# STM32F427 register map
File version: 1.4
CPU: CM4 r0p1, little endian, MPU, FPU, 4 interrupt priority bits
Registers are 32-bit, read-write, reset 0x0 unless marked. A register's access mark holds for its fields unless they carry their own. Offsets are from the block's base; [hi:lo] are bit positions; {n}, {i} and the like mark numbered series.

## OTG_FS_PWRCLK — USB on the go full speed
Base 0x50000E00
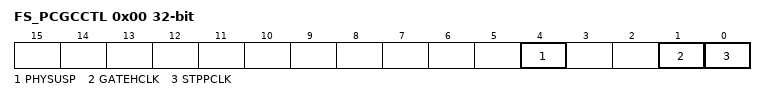
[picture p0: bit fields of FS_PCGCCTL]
0x00 FS_PCGCCTL — OTG_FS power and clock gating control register (OTG_FS_PCGCCTL)
  [4] PHYSUSP — PHY Suspended
  [1] GATEHCLK
  [0] STPPCLK — Stop PHY clock

## NVIC — Nested Vectored Interrupt Controller
Base 0xE000E100
{0x0+4i} ISER{i} (i=0..2) — Interrupt Set-Enable Register
  [31:0] SETENA
{0x80+4i} ICER{i} (i=0..2) — Interrupt Clear-Enable Register
  [31:0] CLRENA
{0x100+4i} ISPR{i} (i=0..2) — Interrupt Set-Pending Register
  [31:0] SETPEND
{0x180+4i} ICPR{i} (i=0..2) — Interrupt Clear-Pending Register
  [31:0] CLRPEND
{0x200+4i} IABR{i} ro (i=0..2) — Interrupt Active Bit Register
  [31:0] ACTIVE
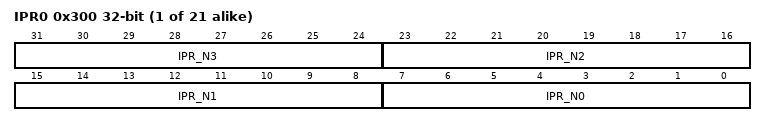
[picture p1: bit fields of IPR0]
{0x300+4i} IPR{i} (i=0..20) — Interrupt Priority Register
  [8n+7:8n] IPR_N{n} (n=0..3)

## FLASH
Base 0x40023C00
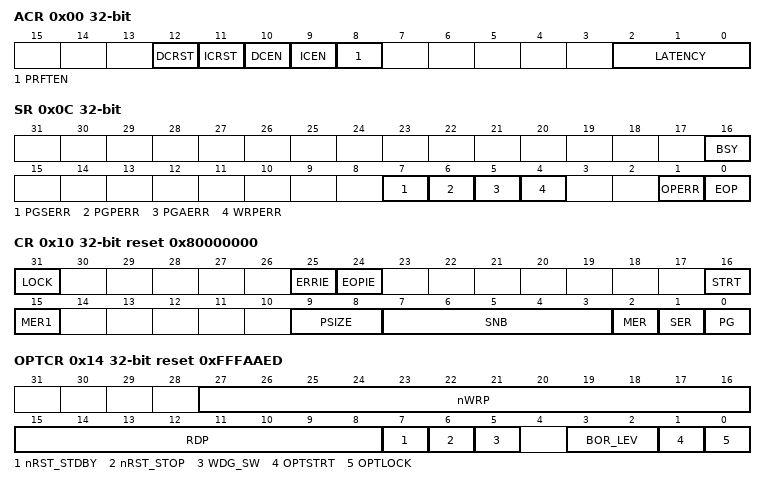
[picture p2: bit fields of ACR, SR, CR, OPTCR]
0x00 ACR access per field — Flash access control register
  [12] DCRST rw — Data cache reset
  [11] ICRST wo — Instruction cache reset
  [10] DCEN rw — Data cache enable
  [9] ICEN rw — Instruction cache enable
  [8] PRFTEN rw — Prefetch enable
  [2:0] LATENCY rw
0x04 KEYR wo — Flash key register
  [31:0] KEY — FPEC key
0x08 OPTKEYR wo — Flash option key register
  [31:0] OPTKEY — Option byte key
0x0C SR access per field — Status register
  [16] BSY ro — Busy
  [7] PGSERR rw — Programming sequence error
  [6] PGPERR rw — Programming parallelism error
  [5] PGAERR rw — Programming alignment error
  [4] WRPERR rw — Write protection error
  [1] OPERR rw — Operation error
  [0] EOP rw — End of operation
0x10 CR reset 0x80000000 — Control register
  [31] LOCK
  [25] ERRIE — Error interrupt enable
  [24] EOPIE — End of operation interrupt enable
  [16] STRT — Start
  [15] MER1 — Mass Erase of sectors 12 to 23
  [9:8] PSIZE — Program size
  [7:3] SNB — Sector number
  [2] MER — Mass Erase of sectors 0 to 11
  [1] SER — Sector Erase
  [0] PG — Programming
0x14 OPTCR reset 0xFFFAAED — Flash option control register
  [27:16] nWRP — Not write protect
  [15:8] RDP — Read protect
  [7] nRST_STDBY — nRST_STDBY User option bytes
  [6] nRST_STOP — nRST_STOP User option bytes
  [5] WDG_SW — WDG_SW User option bytes
  [3:2] BOR_LEV — BOR reset Level
  [1] OPTSTRT — Option start
  [0] OPTLOCK — Option lock
0x18 OPTCR1 reset 0xFFF0000 — Flash option control register 1
  [27:16] nWRP — Not write protect

## EXTI — External interrupt/event controller
Base 0x40013C00
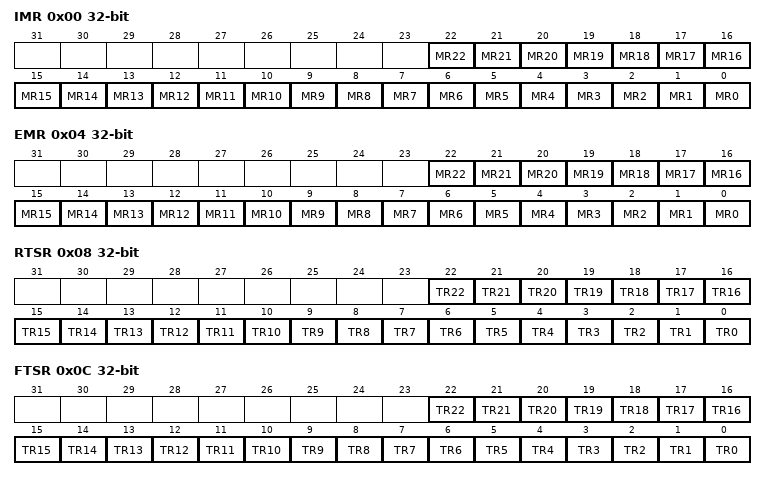
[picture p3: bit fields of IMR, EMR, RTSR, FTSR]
0x00 IMR — Interrupt mask register (EXTI_IMR)
  [n] MR{n} (n=0..22) — Interrupt Mask on line {n}
0x04 EMR — Event mask register (EXTI_EMR)
  [n] MR{n} (n=0..22) — Event Mask on line {n}
0x08 RTSR — Rising Trigger selection register (EXTI_RTSR)
  [n] TR{n} (n=0..22) — Rising trigger event configuration of line {n}
0x0C FTSR — Falling Trigger selection register (EXTI_FTSR)
  [n] TR{n} (n=0..22) — Falling trigger event configuration of line {n}
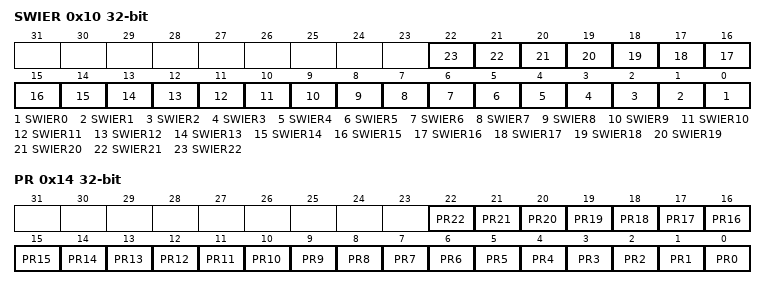
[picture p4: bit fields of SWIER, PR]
0x10 SWIER — Software interrupt event register (EXTI_SWIER)
  [n] SWIER{n} (n=0..22) — Software Interrupt on line {n}
0x14 PR — Pending register (EXTI_PR)
  [n] PR{n} (n=0..22) — Pending bit {n}

## OTG_HS_PWRCLK — USB on the go high speed
Base 0x40040E00
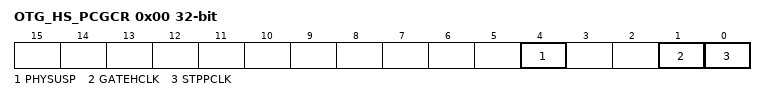
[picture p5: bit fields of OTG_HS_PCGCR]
0x00 OTG_HS_PCGCR — Power and clock gating control register
  [4] PHYSUSP — PHY suspended
  [1] GATEHCLK
  [0] STPPCLK — Stop PHY clock

## I2C3 — Inter-integrated circuit
Base 0x40005C00
Same registers: I2C1 0x40005400, I2C2 0x40005800
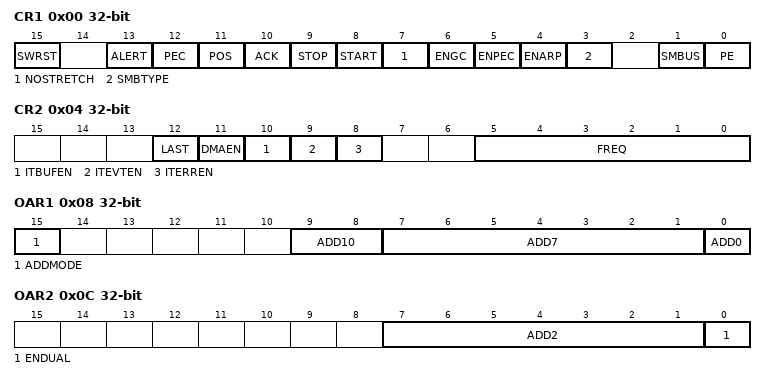
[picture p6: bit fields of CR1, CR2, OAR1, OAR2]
0x00 CR1 — Control register 1
  [15] SWRST — Software reset
  [13] ALERT — SMBus alert
  [12] PEC — Packet error checking
  [11] POS — Acknowledge/PEC Position (for data reception)
  [10] ACK — Acknowledge enable
  [9] STOP — Stop generation
  [8] START — Start generation
  [7] NOSTRETCH — Clock stretching disable (Slave mode)
  [6] ENGC — General call enable
  [5] ENPEC — PEC enable
  [4] ENARP — ARP enable
  [3] SMBTYPE — SMBus type
  [1] SMBUS — SMBus mode
  [0] PE — Peripheral enable
0x04 CR2 — Control register 2
  [12] LAST — DMA last transfer
  [11] DMAEN — DMA requests enable
  [10] ITBUFEN — Buffer interrupt enable
  [9] ITEVTEN — Event interrupt enable
  [8] ITERREN — Error interrupt enable
  [5:0] FREQ — Peripheral clock frequency
0x08 OAR1 — Own address register 1
  [15] ADDMODE — Addressing mode (slave mode)
  [9:8] ADD10 — Interface address
  [7:1] ADD7 — Interface address
  [0] ADD0 — Interface address
0x0C OAR2 — Own address register 2
  [7:1] ADD2 — Interface address
  [0] ENDUAL — Dual addressing mode enable
0x10 DR — Data register
  [7:0] DR — 8-bit data register
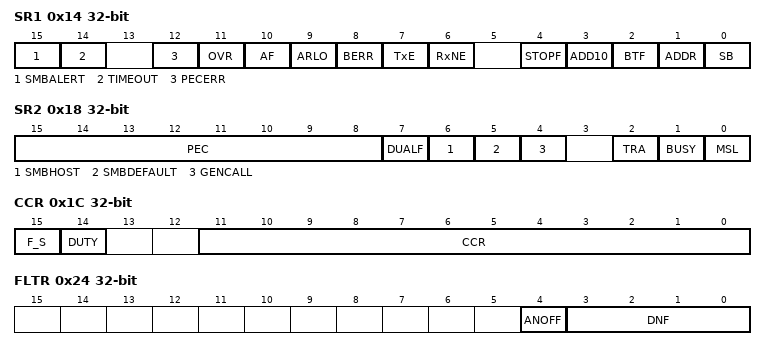
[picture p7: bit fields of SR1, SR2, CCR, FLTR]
0x14 SR1 access per field — Status register 1
  [15] SMBALERT rw — SMBus alert
  [14] TIMEOUT rw — Timeout or Tlow error
  [12] PECERR rw — PEC Error in reception
  [11] OVR rw — Overrun/Underrun
  [10] AF rw — Acknowledge failure
  [9] ARLO rw — Arbitration lost (master mode)
  [8] BERR rw — Bus error
  [7] TxE ro — Data register empty (transmitters)
  [6] RxNE ro — Data register not empty (receivers)
  [4] STOPF ro — Stop detection (slave mode)
  [3] ADD10 ro — 10-bit header sent (Master mode)
  [2] BTF ro — Byte transfer finished
  [1] ADDR ro — Address sent (master mode)/matched (slave mode)
  [0] SB ro — Start bit (Master mode)
0x18 SR2 ro — Status register 2
  [15:8] PEC — acket error checking register
  [7] DUALF — Dual flag (Slave mode)
  [6] SMBHOST — SMBus host header (Slave mode)
  [5] SMBDEFAULT — SMBus device default address (Slave mode)
  [4] GENCALL — General call address (Slave mode)
  [2] TRA — Transmitter/receiver
  [1] BUSY — Bus busy
  [0] MSL — Master/slave
0x1C CCR — Clock control register
  [15] F_S — I2C master mode selection
  [14] DUTY — Fast mode duty cycle
  [11:0] CCR — Clock control register in Fast/Standard mode (Master mode)
0x20 TRISE reset 0x2
  [5:0] TRISE — Maximum rise time in Fast/Standard mode (Master mode)
0x24 FLTR — I2C FLTR register
  [4] ANOFF — Analog noise filter OFF
  [3:0] DNF — Digital noise filter
